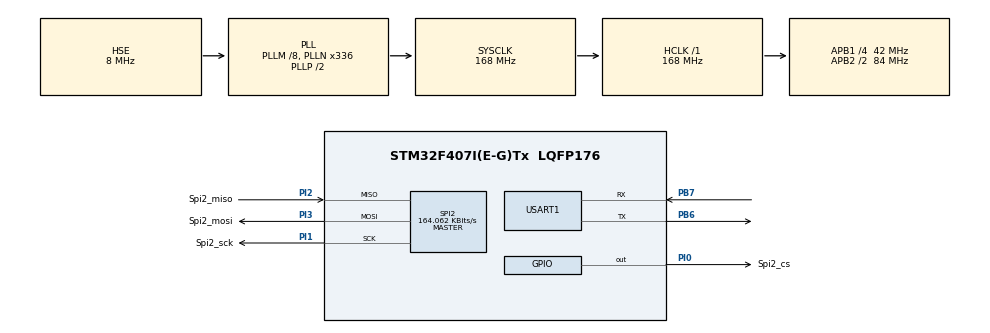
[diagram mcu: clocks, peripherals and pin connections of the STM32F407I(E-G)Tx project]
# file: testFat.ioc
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FATFS._CODE_PAGE=936
FATFS._MAX_SS=512
FATFS._MIN_SS=512
FATFS._USE_LABEL=1
FATFS._USE_LFN=3
FREERTOS.Tasks01=defaultTask,0,1024,StartDefaultTask,Default,NULL,Dynamic,NULL,NULL
Mcu.Family=STM32F4
Mcu.Name=STM32F407I(E-G)Tx
Mcu.Package=LQFP176
NVIC.PriorityGroup=NVIC_PRIORITYGROUP_4
NVIC.TIM1_UP_TIM10_IRQn=true\:0\:0\:false\:false\:true\:false\:false\:true
NVIC.TimeBase=TIM1_UP_TIM10_IRQn
NVIC.TimeBaseIP=TIM1
PA13.Mode=Serial_Wire
PA13.Signal=SYS_JTMS-SWDIO
PA14.Mode=Serial_Wire
PA14.Signal=SYS_JTCK-SWCLK
PB6.Mode=Asynchronous
PB6.Signal=USART1_TX
PB7.Mode=Asynchronous
PB7.Signal=USART1_RX
PH0-OSC_IN.Mode=HSE-External-Oscillator
PH0-OSC_IN.Signal=RCC_OSC_IN
PH1-OSC_OUT.Mode=HSE-External-Oscillator
PH1-OSC_OUT.Signal=RCC_OSC_OUT
PI0.GPIO_Label=Spi2_cs
PI0.GPIO_PuPd=GPIO_PULLUP
PI0.GPIO_Speed=GPIO_SPEED_FREQ_HIGH
PI0.PinState=GPIO_PIN_SET
PI0.Signal=GPIO_Output
PI1.GPIO_Label=Spi2_sck
PI1.GPIO_PuPd=GPIO_PULLUP
PI1.Mode=Full_Duplex_Master
PI1.Signal=SPI2_SCK
PI2.GPIO_Label=Spi2_miso
PI2.GPIO_PuPd=GPIO_PULLUP
PI2.Mode=Full_Duplex_Master
PI2.Signal=SPI2_MISO
PI3.GPIO_Label=Spi2_mosi
PI3.GPIO_PuPd=GPIO_PULLUP
PI3.Mode=Full_Duplex_Master
PI3.Signal=SPI2_MOSI
ProjectManager.HeapSize=0x1000
ProjectManager.StackSize=0x400
ProjectManager.TargetToolchain=MDK-ARM V5
RCC.48MHZClocksFreq_Value=84000000
RCC.AHBFreq_Value=168000000
RCC.APB1CLKDivider=RCC_HCLK_DIV4
RCC.APB1Freq_Value=42000000
RCC.APB1TimFreq_Value=84000000
RCC.APB2CLKDivider=RCC_HCLK_DIV2
RCC.APB2Freq_Value=84000000
RCC.APB2TimFreq_Value=168000000
RCC.CortexFreq_Value=168000000
RCC.HCLKFreq_Value=168000000
RCC.HSE_VALUE=8000000
RCC.HSI_VALUE=16000000
RCC.LSE_VALUE=32768
RCC.PLLM=8
RCC.PLLN=336
RCC.PLLSourceVirtual=RCC_PLLSOURCE_HSE
RCC.SYSCLKFreq_VALUE=168000000
RCC.SYSCLKSource=RCC_SYSCLKSOURCE_PLLCLK
RCC.VCOOutputFreq_Value=336000000
SPI2.BaudRatePrescaler=SPI_BAUDRATEPRESCALER_256
SPI2.CLKPhase=SPI_PHASE_2EDGE
SPI2.CLKPolarity=SPI_POLARITY_HIGH
SPI2.CalculateBaudRate=164.062 KBits/s
SPI2.Direction=SPI_DIRECTION_2LINES
SPI2.Mode=SPI_MODE_MASTER
SPI2.VirtualType=VM_MASTER
USART1.VirtualMode=VM_ASYNC
VP_FATFS_VS_Generic.Mode=User_defined
VP_FREERTOS_VS_CMSIS_V1.Mode=CMSIS_V1
VP_SYS_VS_tim1.Mode=TIM1
board=custom

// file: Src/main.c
/* USER CODE BEGIN Header */
/**
  ******************************************************************************
  * @file           : main.c
  * @brief          : Main program body
  ******************************************************************************
  * @attention
  *
  * <h2><center>&copy; Copyright (c) 2024 STMicroelectronics.
  * All rights reserved.</center></h2>
  *
  * This software component is licensed by ST under Ultimate Liberty license
  * SLA0044, the "License"; You may not use this file except in compliance with
  * the License. You may obtain a copy of the License at:
  *                             www.st.com/SLA0044
  *
  ******************************************************************************
  */
/* USER CODE END Header */

#include "main.h"
#include "cmsis_os.h"
#include "fatfs.h"
#include "spi.h"
#include "usart.h"
#include "gpio.h"

/* USER CODE BEGIN Includes */
#include "norflash.h"
/* USER CODE END Includes */

/* USER CODE BEGIN PD */
uint16_t id;  //norflash id
/* USER CODE END PD */

void SystemClock_Config(void);
void MX_FREERTOS_Init(void);

int main(void)
{

  /* MCU Configuration--------------------------------------------------------*/

  /* Reset of all peripherals, Initializes the Flash interface and the Systick. */
  HAL_Init();

  /* Configure the system clock */
  SystemClock_Config();

  /* Initialize all configured peripherals */
  MX_GPIO_Init();
  MX_SPI2_Init();
  MX_USART1_UART_Init();
  /* USER CODE BEGIN 2 */

	//SPI Flash
	//norflash_init();  //初始化norflash

  /* USER CODE END 2 */

  /* Call init function for freertos objects (in freertos.c) */
  MX_FREERTOS_Init();

  /* Start scheduler */
  osKernelStart();

  /* We should never get here as control is now taken by the scheduler */

  /* Infinite loop */
  while (1)
  {

  }
}

void SystemClock_Config(void)
{
  RCC_OscInitTypeDef RCC_OscInitStruct = {0};
  RCC_ClkInitTypeDef RCC_ClkInitStruct = {0};

  /** Configure the main internal regulator output voltage
  */
  __HAL_RCC_PWR_CLK_ENABLE();
  __HAL_PWR_VOLTAGESCALING_CONFIG(PWR_REGULATOR_VOLTAGE_SCALE1);
  /** Initializes the CPU, AHB and APB busses clocks
  */
  RCC_OscInitStruct.OscillatorType = RCC_OSCILLATORTYPE_HSE;
  RCC_OscInitStruct.HSEState = RCC_HSE_ON;
  RCC_OscInitStruct.PLL.PLLState = RCC_PLL_ON;
  RCC_OscInitStruct.PLL.PLLSource = RCC_PLLSOURCE_HSE;
  RCC_OscInitStruct.PLL.PLLM = 8;
  RCC_OscInitStruct.PLL.PLLN = 336;
  RCC_OscInitStruct.PLL.PLLP = RCC_PLLP_DIV2;
  RCC_OscInitStruct.PLL.PLLQ = 4;
  if (HAL_RCC_OscConfig(&RCC_OscInitStruct) != HAL_OK)
  {
    Error_Handler();
  }
  /** Initializes the CPU, AHB and APB busses clocks
  */
  RCC_ClkInitStruct.ClockType = RCC_CLOCKTYPE_HCLK|RCC_CLOCKTYPE_SYSCLK
                              |RCC_CLOCKTYPE_PCLK1|RCC_CLOCKTYPE_PCLK2;
  RCC_ClkInitStruct.SYSCLKSource = RCC_SYSCLKSOURCE_PLLCLK;
  RCC_ClkInitStruct.AHBCLKDivider = RCC_SYSCLK_DIV1;
  RCC_ClkInitStruct.APB1CLKDivider = RCC_HCLK_DIV4;
  RCC_ClkInitStruct.APB2CLKDivider = RCC_HCLK_DIV2;

  if (HAL_RCC_ClockConfig(&RCC_ClkInitStruct, FLASH_LATENCY_5) != HAL_OK)
  {
    Error_Handler();
  }
}

void HAL_TIM_PeriodElapsedCallback(TIM_HandleTypeDef *htim)
{
  if (htim->Instance == TIM1) {
    HAL_IncTick();
  }
}

void Error_Handler(void)
{
}

/************************ (C) COPYRIGHT STMicroelectronics *****END OF FILE****/

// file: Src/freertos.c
/* USER CODE BEGIN Header */
/**
  ******************************************************************************
  * File Name          : freertos.c
  * Description        : Code for freertos applications
  ******************************************************************************
  * @attention
  *
  * <h2><center>&copy; Copyright (c) 2024 STMicroelectronics.
  * All rights reserved.</center></h2>
  *
  * This software component is licensed by ST under Ultimate Liberty license
  * SLA0044, the "License"; You may not use this file except in compliance with
  * the License. You may obtain a copy of the License at:
  *                             www.st.com/SLA0044
  *
  ******************************************************************************
  */
/* USER CODE END Header */

#include "FreeRTOS.h"
#include "task.h"
#include "main.h"
#include "cmsis_os.h"

/* USER CODE BEGIN Includes */
#include "usart.h"

#include "norflash.h"

#include "ff.h"  //f_mount
#include "fatfs.h"  //USERFatFS USERPath
/* USER CODE END Includes */

osThreadId defaultTaskHandle;

void StartDefaultTask(void const * argument);

extern void MX_FATFS_Init(void);
void MX_FREERTOS_Init(void); /* (MISRA C 2004 rule 8.1) */

/* GetIdleTaskMemory prototype (linked to static allocation support) */
void vApplicationGetIdleTaskMemory( StaticTask_t **ppxIdleTaskTCBBuffer, StackType_t **ppxIdleTaskStackBuffer, uint32_t *pulIdleTaskStackSize );

/* USER CODE BEGIN GET_IDLE_TASK_MEMORY */
static StaticTask_t xIdleTaskTCBBuffer;
static StackType_t xIdleStack[configMINIMAL_STACK_SIZE];

void vApplicationGetIdleTaskMemory( StaticTask_t **ppxIdleTaskTCBBuffer, StackType_t **ppxIdleTaskStackBuffer, uint32_t *pulIdleTaskStackSize )
{
  *ppxIdleTaskTCBBuffer = &xIdleTaskTCBBuffer;
  *ppxIdleTaskStackBuffer = &xIdleStack[0];
  *pulIdleTaskStackSize = configMINIMAL_STACK_SIZE;
  /* place for user code */
}
/* USER CODE END GET_IDLE_TASK_MEMORY */

void MX_FREERTOS_Init(void) {

  /* Create the thread(s) */
  /* definition and creation of defaultTask */
  osThreadDef(defaultTask, StartDefaultTask, osPriorityNormal, 0, 1024);
  defaultTaskHandle = osThreadCreate(osThread(defaultTask), NULL);

}

void StartDefaultTask(void const * argument)
{

  /* init code for FATFS */
  MX_FATFS_Init();

  /* USER CODE BEGIN StartDefaultTask */
	printf("system is running, fatfs is ok!\n");
	/*
	uint8_t u8chr[] = "hello";
	uint32_t u32Wbytes;
	#define STRSIZE sizeof(u8chr)
	uint8_t u8chr_read[STRSIZE] = {0};
	FRESULT res = f_mount(&USERFatFS,USERPath,1);
	printf("f_mount return %d\n", res);

  if(res == FR_OK){
		printf("f_mount right!\n");
		if(f_open(&USERFile,(const char*)"fatfs.txt",FA_READ) == FR_OK){
			printf("f_open fatfs.txt right!\n");
      if(f_read(&USERFile,u8chr_read,sizeof(u8chr),&u32Wbytes) == FR_OK){
				printf("f_read fatfs.txt right!\n");
				printf("read u8chr_read:%s\n", u8chr_read);
        f_close(&USERFile);
				printf("f_close fatfs.txt right!\n");
      }
    }
  }
	*/
  /* Infinite loop */
  for(;;)
  {
    osDelay(1);
  }
  /* USER CODE END StartDefaultTask */
}

/************************ (C) COPYRIGHT STMicroelectronics *****END OF FILE****/
